# CBASS_HC2_0_QOS register map
Vendor: Texas Instruments
Peripheral module from a debugger description file (folder J7_AHP).
Registers are 32-bit, read-write, reset 0x7000 unless marked. A register's access mark holds for its fields unless they carry their own. Offsets are as the file gives them; lines under a group give offsets from that group; [hi:lo] are bit positions; {n}, {i} and the like mark numbered series; 'fields as' and 'values as' point back to an identical list; <NAME> marks a mode.

## CBASS_HC2_0_QOS
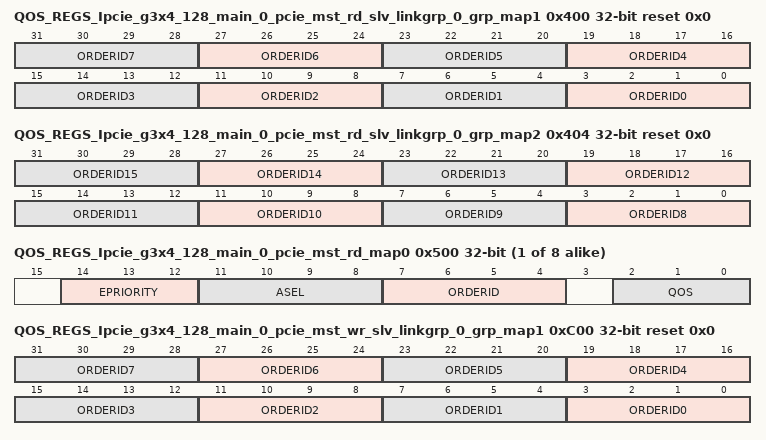
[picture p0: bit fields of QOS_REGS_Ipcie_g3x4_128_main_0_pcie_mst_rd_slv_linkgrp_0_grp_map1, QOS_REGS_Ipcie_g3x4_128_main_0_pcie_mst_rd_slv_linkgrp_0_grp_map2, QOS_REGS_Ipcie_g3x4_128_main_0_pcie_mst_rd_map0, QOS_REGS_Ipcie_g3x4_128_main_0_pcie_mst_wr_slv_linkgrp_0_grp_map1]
0x400 QOS_REGS_Ipcie_g3x4_128_main_0_pcie_mst_rd_slv_linkgrp_0_grp_map1 reset 0x0
  [4n+3:4n] ORDERID{n} (n=0..7) — orderid signal for {n}.
0x404 QOS_REGS_Ipcie_g3x4_128_main_0_pcie_mst_rd_slv_linkgrp_0_grp_map2 reset 0x0
  [4n-29:4n-32] ORDERID{n} (n=8..15) — orderid signal for {n-8}.
{0x500+4i} QOS_REGS_Ipcie_g3x4_128_main_0_pcie_mst_rd_map{i} (i=0..7)
  [14:12] EPRIORITY — epriority signal for channel N.
  [11:8] ASEL — asel signal for channel N. 0 = SOC address. 1-15 = peripheral address.
  [7:4] ORDERID — orderid signal for channel N.
  [2:0] QOS — qos signal for channel N.
0xC00 QOS_REGS_Ipcie_g3x4_128_main_0_pcie_mst_wr_slv_linkgrp_0_grp_map1 reset 0x0
  [4n+3:4n] ORDERID{n} (n=0..7) — orderid signal for {n}.
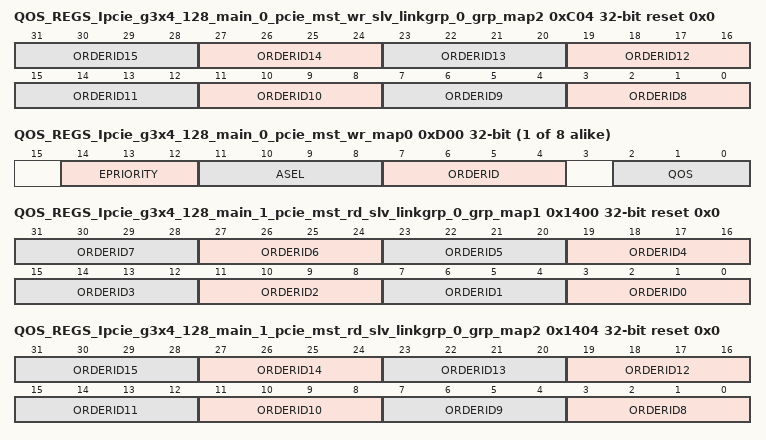
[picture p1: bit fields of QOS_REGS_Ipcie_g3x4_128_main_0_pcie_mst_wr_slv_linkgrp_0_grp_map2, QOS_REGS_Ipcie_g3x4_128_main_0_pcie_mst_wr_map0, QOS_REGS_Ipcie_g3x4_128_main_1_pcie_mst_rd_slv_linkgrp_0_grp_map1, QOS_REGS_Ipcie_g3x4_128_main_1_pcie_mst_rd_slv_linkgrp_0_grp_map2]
0xC04 QOS_REGS_Ipcie_g3x4_128_main_0_pcie_mst_wr_slv_linkgrp_0_grp_map2 reset 0x0
  [4n-29:4n-32] ORDERID{n} (n=8..15) — orderid signal for {n-8}.
{0xD00+4i} QOS_REGS_Ipcie_g3x4_128_main_0_pcie_mst_wr_map{i} (i=0..7)
  fields as QOS_REGS_Ipcie_g3x4_128_main_0_pcie_mst_rd_map0
0x1400 QOS_REGS_Ipcie_g3x4_128_main_1_pcie_mst_rd_slv_linkgrp_0_grp_map1 reset 0x0
  [4n+3:4n] ORDERID{n} (n=0..7) — orderid signal for {n}.
0x1404 QOS_REGS_Ipcie_g3x4_128_main_1_pcie_mst_rd_slv_linkgrp_0_grp_map2 reset 0x0
  [4n-29:4n-32] ORDERID{n} (n=8..15) — orderid signal for {n-8}.
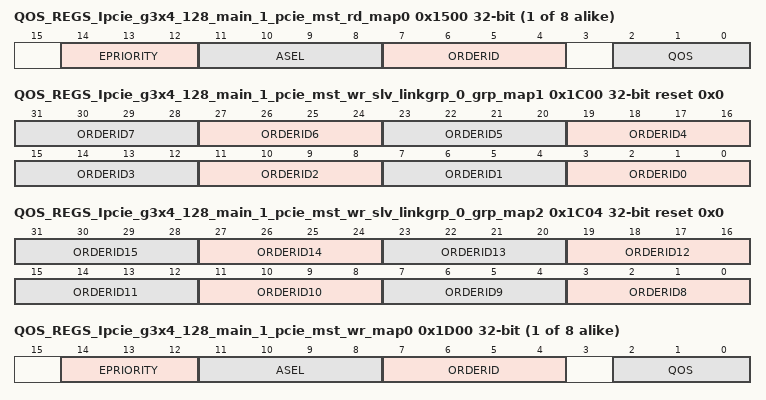
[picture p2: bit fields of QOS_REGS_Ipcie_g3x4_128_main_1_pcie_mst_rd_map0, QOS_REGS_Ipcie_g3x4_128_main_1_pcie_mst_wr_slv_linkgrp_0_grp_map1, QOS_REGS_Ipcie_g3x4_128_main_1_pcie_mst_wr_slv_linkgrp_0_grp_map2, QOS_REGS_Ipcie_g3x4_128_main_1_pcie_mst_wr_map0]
{0x1500+4i} QOS_REGS_Ipcie_g3x4_128_main_1_pcie_mst_rd_map{i} (i=0..7)
  fields as QOS_REGS_Ipcie_g3x4_128_main_0_pcie_mst_rd_map0
0x1C00 QOS_REGS_Ipcie_g3x4_128_main_1_pcie_mst_wr_slv_linkgrp_0_grp_map1 reset 0x0
  [4n+3:4n] ORDERID{n} (n=0..7) — orderid signal for {n}.
0x1C04 QOS_REGS_Ipcie_g3x4_128_main_1_pcie_mst_wr_slv_linkgrp_0_grp_map2 reset 0x0
  [4n-29:4n-32] ORDERID{n} (n=8..15) — orderid signal for {n-8}.
{0x1D00+4i} QOS_REGS_Ipcie_g3x4_128_main_1_pcie_mst_wr_map{i} (i=0..7)
  fields as QOS_REGS_Ipcie_g3x4_128_main_0_pcie_mst_rd_map0
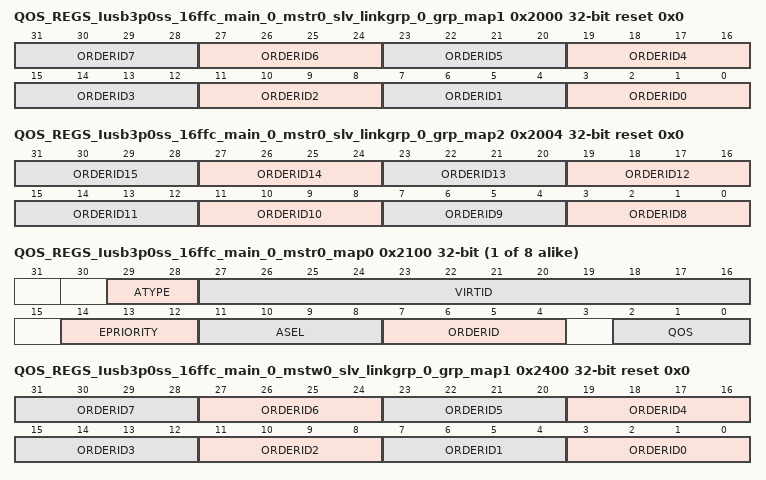
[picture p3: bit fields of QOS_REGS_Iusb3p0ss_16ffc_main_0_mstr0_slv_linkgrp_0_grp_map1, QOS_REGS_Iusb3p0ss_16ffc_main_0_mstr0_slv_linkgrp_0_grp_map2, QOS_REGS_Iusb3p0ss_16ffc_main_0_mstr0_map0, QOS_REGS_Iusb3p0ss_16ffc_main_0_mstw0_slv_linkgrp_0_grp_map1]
0x2000 QOS_REGS_Iusb3p0ss_16ffc_main_0_mstr0_slv_linkgrp_0_grp_map1 reset 0x0
  [4n+3:4n] ORDERID{n} (n=0..7) — orderid signal for {n}.
0x2004 QOS_REGS_Iusb3p0ss_16ffc_main_0_mstr0_slv_linkgrp_0_grp_map2 reset 0x0
  [4n-29:4n-32] ORDERID{n} (n=8..15) — orderid signal for {n-8}.
{0x2100+4i} QOS_REGS_Iusb3p0ss_16ffc_main_0_mstr0_map{i} (i=0..7)
  [29:28] ATYPE — epriority signal for channel N. 0 = physical. 1 = intermediate. 2 = virtual. 3 = physical with coherence.
  [27:16] VIRTID — virtid signal for channel N.
  [14:12] EPRIORITY — epriority signal for channel N.
  [11:8] ASEL — asel signal for channel N. 0 = SOC address. 1-15 = peripheral address.
  [7:4] ORDERID — orderid signal for channel N.
  [2:0] QOS — qos signal for channel N.
0x2400 QOS_REGS_Iusb3p0ss_16ffc_main_0_mstw0_slv_linkgrp_0_grp_map1 reset 0x0
  [4n+3:4n] ORDERID{n} (n=0..7) — orderid signal for {n}.
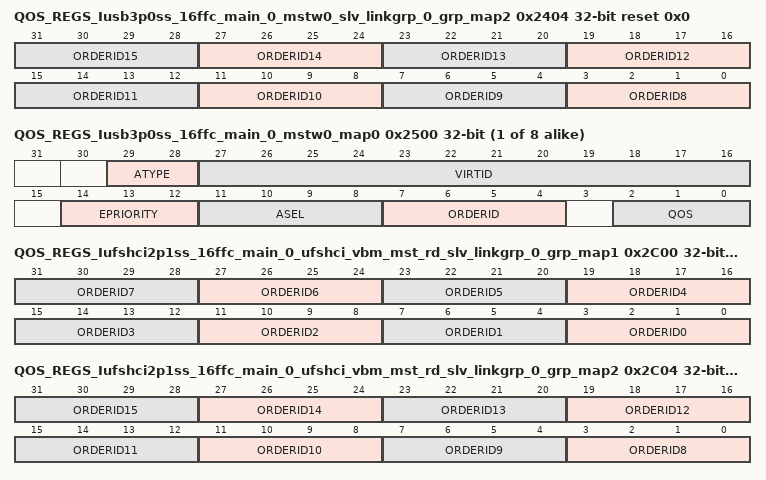
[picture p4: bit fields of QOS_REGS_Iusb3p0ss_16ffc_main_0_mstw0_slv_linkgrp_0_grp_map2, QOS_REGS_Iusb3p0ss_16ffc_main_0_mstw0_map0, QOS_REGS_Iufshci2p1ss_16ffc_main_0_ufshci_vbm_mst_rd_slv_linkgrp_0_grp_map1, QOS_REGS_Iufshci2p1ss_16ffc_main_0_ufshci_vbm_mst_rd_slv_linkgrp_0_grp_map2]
0x2404 QOS_REGS_Iusb3p0ss_16ffc_main_0_mstw0_slv_linkgrp_0_grp_map2 reset 0x0
  [4n-29:4n-32] ORDERID{n} (n=8..15) — orderid signal for {n-8}.
{0x2500+4i} QOS_REGS_Iusb3p0ss_16ffc_main_0_mstw0_map{i} (i=0..7)
  fields as QOS_REGS_Iusb3p0ss_16ffc_main_0_mstr0_map0
0x2C00 QOS_REGS_Iufshci2p1ss_16ffc_main_0_ufshci_vbm_mst_rd_slv_linkgrp_0_grp_map1 reset 0x0
  [4n+3:4n] ORDERID{n} (n=0..7) — orderid signal for {n}.
0x2C04 QOS_REGS_Iufshci2p1ss_16ffc_main_0_ufshci_vbm_mst_rd_slv_linkgrp_0_grp_map2 reset 0x0
  [4n-29:4n-32] ORDERID{n} (n=8..15) — orderid signal for {n-8}.
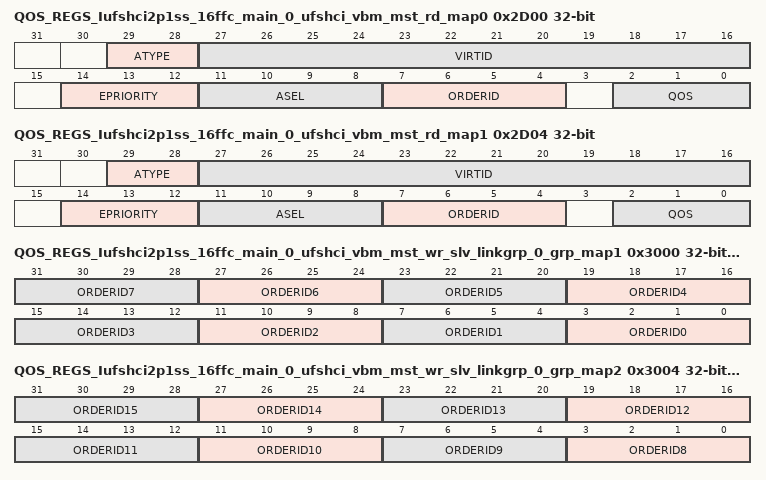
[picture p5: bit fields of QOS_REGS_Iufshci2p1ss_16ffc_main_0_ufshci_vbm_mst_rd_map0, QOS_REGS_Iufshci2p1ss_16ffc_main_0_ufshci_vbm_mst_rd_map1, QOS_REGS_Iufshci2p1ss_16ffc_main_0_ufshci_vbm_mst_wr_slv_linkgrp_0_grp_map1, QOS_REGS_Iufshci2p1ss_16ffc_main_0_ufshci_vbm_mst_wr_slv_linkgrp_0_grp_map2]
0x2D00 QOS_REGS_Iufshci2p1ss_16ffc_main_0_ufshci_vbm_mst_rd_map0
  fields as QOS_REGS_Iusb3p0ss_16ffc_main_0_mstr0_map0
0x2D04 QOS_REGS_Iufshci2p1ss_16ffc_main_0_ufshci_vbm_mst_rd_map1
  fields as QOS_REGS_Iusb3p0ss_16ffc_main_0_mstr0_map0
0x3000 QOS_REGS_Iufshci2p1ss_16ffc_main_0_ufshci_vbm_mst_wr_slv_linkgrp_0_grp_map1 reset 0x0
  [4n+3:4n] ORDERID{n} (n=0..7) — orderid signal for {n}.
0x3004 QOS_REGS_Iufshci2p1ss_16ffc_main_0_ufshci_vbm_mst_wr_slv_linkgrp_0_grp_map2 reset 0x0
  [4n-29:4n-32] ORDERID{n} (n=8..15) — orderid signal for {n-8}.
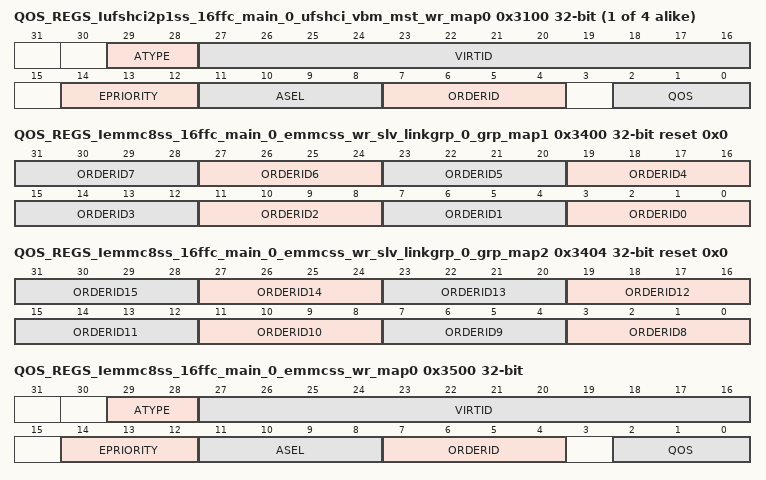
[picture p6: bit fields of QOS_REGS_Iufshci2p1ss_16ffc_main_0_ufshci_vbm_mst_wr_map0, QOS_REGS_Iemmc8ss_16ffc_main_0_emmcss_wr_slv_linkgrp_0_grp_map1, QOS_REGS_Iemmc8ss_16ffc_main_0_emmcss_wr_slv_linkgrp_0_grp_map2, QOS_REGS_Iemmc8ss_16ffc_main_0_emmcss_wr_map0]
{0x3100+4i} QOS_REGS_Iufshci2p1ss_16ffc_main_0_ufshci_vbm_mst_wr_map{i} (i=0..3)
  fields as QOS_REGS_Iusb3p0ss_16ffc_main_0_mstr0_map0
0x3400 QOS_REGS_Iemmc8ss_16ffc_main_0_emmcss_wr_slv_linkgrp_0_grp_map1 reset 0x0
  [4n+3:4n] ORDERID{n} (n=0..7) — orderid signal for {n}.
0x3404 QOS_REGS_Iemmc8ss_16ffc_main_0_emmcss_wr_slv_linkgrp_0_grp_map2 reset 0x0
  [4n-29:4n-32] ORDERID{n} (n=8..15) — orderid signal for {n-8}.
0x3500 QOS_REGS_Iemmc8ss_16ffc_main_0_emmcss_wr_map0
  fields as QOS_REGS_Iusb3p0ss_16ffc_main_0_mstr0_map0
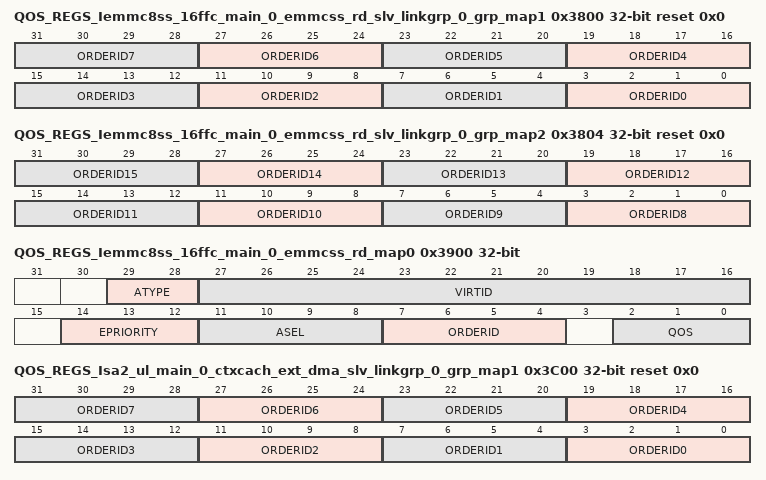
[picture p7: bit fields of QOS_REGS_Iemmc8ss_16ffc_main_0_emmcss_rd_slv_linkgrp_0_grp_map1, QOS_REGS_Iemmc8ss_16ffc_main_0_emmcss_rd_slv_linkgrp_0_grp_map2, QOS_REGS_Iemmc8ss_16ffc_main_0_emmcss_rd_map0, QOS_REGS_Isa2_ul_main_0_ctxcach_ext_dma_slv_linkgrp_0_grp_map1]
0x3800 QOS_REGS_Iemmc8ss_16ffc_main_0_emmcss_rd_slv_linkgrp_0_grp_map1 reset 0x0
  [4n+3:4n] ORDERID{n} (n=0..7) — orderid signal for {n}.
0x3804 QOS_REGS_Iemmc8ss_16ffc_main_0_emmcss_rd_slv_linkgrp_0_grp_map2 reset 0x0
  [4n-29:4n-32] ORDERID{n} (n=8..15) — orderid signal for {n-8}.
0x3900 QOS_REGS_Iemmc8ss_16ffc_main_0_emmcss_rd_map0
  fields as QOS_REGS_Iusb3p0ss_16ffc_main_0_mstr0_map0
0x3C00 QOS_REGS_Isa2_ul_main_0_ctxcach_ext_dma_slv_linkgrp_0_grp_map1 reset 0x0
  [4n+3:4n] ORDERID{n} (n=0..7) — orderid signal for {n}.
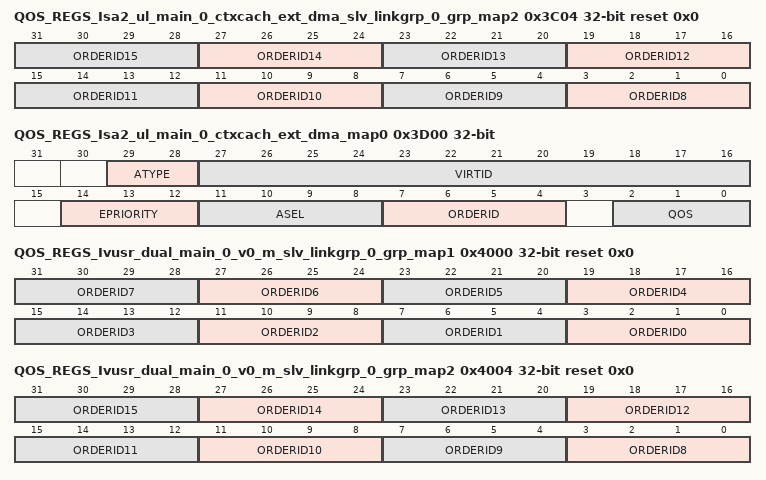
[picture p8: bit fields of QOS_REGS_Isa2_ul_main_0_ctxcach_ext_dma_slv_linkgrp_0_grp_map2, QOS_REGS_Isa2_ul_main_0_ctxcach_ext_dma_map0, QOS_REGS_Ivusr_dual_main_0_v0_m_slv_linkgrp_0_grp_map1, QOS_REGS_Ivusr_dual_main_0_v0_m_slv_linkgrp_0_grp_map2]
0x3C04 QOS_REGS_Isa2_ul_main_0_ctxcach_ext_dma_slv_linkgrp_0_grp_map2 reset 0x0
  [4n-29:4n-32] ORDERID{n} (n=8..15) — orderid signal for {n-8}.
0x3D00 QOS_REGS_Isa2_ul_main_0_ctxcach_ext_dma_map0
  fields as QOS_REGS_Iusb3p0ss_16ffc_main_0_mstr0_map0
0x4000 QOS_REGS_Ivusr_dual_main_0_v0_m_slv_linkgrp_0_grp_map1 reset 0x0
  [4n+3:4n] ORDERID{n} (n=0..7) — orderid signal for {n}.
0x4004 QOS_REGS_Ivusr_dual_main_0_v0_m_slv_linkgrp_0_grp_map2 reset 0x0
  [4n-29:4n-32] ORDERID{n} (n=8..15) — orderid signal for {n-8}.
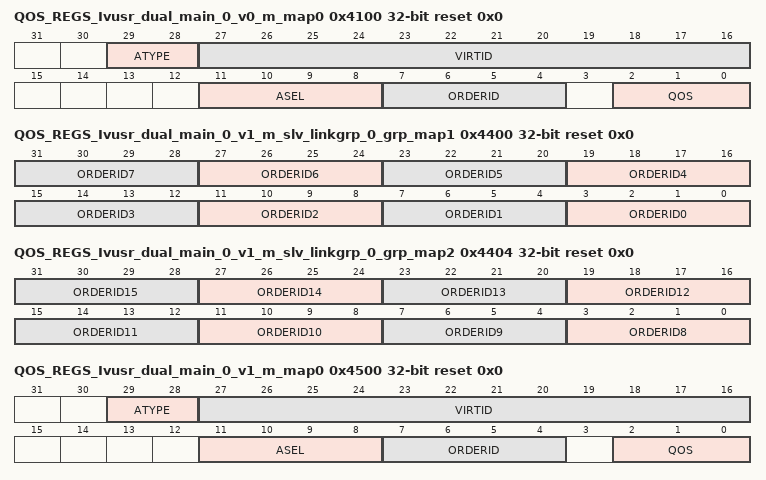
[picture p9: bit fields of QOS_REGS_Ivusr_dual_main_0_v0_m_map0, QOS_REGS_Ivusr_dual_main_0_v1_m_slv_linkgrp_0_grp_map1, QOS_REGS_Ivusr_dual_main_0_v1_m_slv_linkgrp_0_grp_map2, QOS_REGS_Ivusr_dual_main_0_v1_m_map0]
0x4100 QOS_REGS_Ivusr_dual_main_0_v0_m_map0 reset 0x0
  [29:28] ATYPE — epriority signal for channel N. 0 = physical. 1 = intermediate. 2 = virtual. 3 = physical with coherence.
  [27:16] VIRTID — virtid signal for channel N.
  [11:8] ASEL — asel signal for channel N. 0 = SOC address. 1-15 = peripheral address.
  [7:4] ORDERID — orderid signal for channel N.
  [2:0] QOS — qos signal for channel N.
0x4400 QOS_REGS_Ivusr_dual_main_0_v1_m_slv_linkgrp_0_grp_map1 reset 0x0
  [4n+3:4n] ORDERID{n} (n=0..7) — orderid signal for {n}.
0x4404 QOS_REGS_Ivusr_dual_main_0_v1_m_slv_linkgrp_0_grp_map2 reset 0x0
  [4n-29:4n-32] ORDERID{n} (n=8..15) — orderid signal for {n-8}.
0x4500 QOS_REGS_Ivusr_dual_main_0_v1_m_map0 reset 0x0
  fields as QOS_REGS_Ivusr_dual_main_0_v0_m_map0
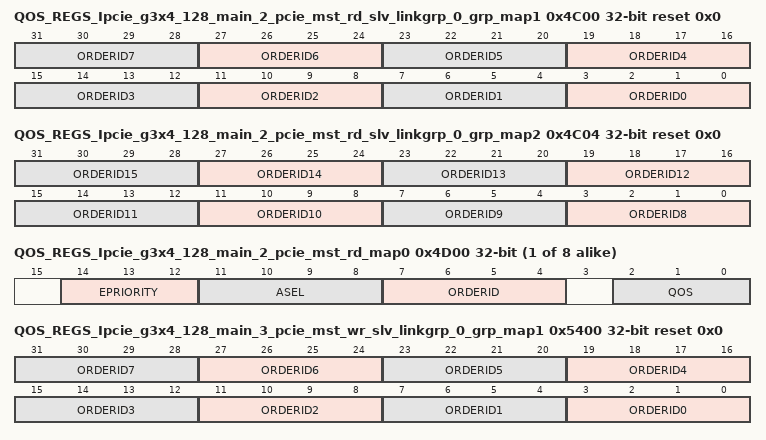
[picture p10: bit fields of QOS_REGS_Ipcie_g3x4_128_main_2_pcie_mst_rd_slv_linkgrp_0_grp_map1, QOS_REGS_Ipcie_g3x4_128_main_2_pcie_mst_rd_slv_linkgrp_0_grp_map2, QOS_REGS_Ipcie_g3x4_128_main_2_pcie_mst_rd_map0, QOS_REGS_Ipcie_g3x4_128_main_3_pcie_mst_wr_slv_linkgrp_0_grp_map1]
0x4C00 QOS_REGS_Ipcie_g3x4_128_main_2_pcie_mst_rd_slv_linkgrp_0_grp_map1 reset 0x0
  [4n+3:4n] ORDERID{n} (n=0..7) — orderid signal for {n}.
0x4C04 QOS_REGS_Ipcie_g3x4_128_main_2_pcie_mst_rd_slv_linkgrp_0_grp_map2 reset 0x0
  [4n-29:4n-32] ORDERID{n} (n=8..15) — orderid signal for {n-8}.
{0x4D00+4i} QOS_REGS_Ipcie_g3x4_128_main_2_pcie_mst_rd_map{i} (i=0..7)
  fields as QOS_REGS_Ipcie_g3x4_128_main_0_pcie_mst_rd_map0
0x5400 QOS_REGS_Ipcie_g3x4_128_main_3_pcie_mst_wr_slv_linkgrp_0_grp_map1 reset 0x0
  [4n+3:4n] ORDERID{n} (n=0..7) — orderid signal for {n}.
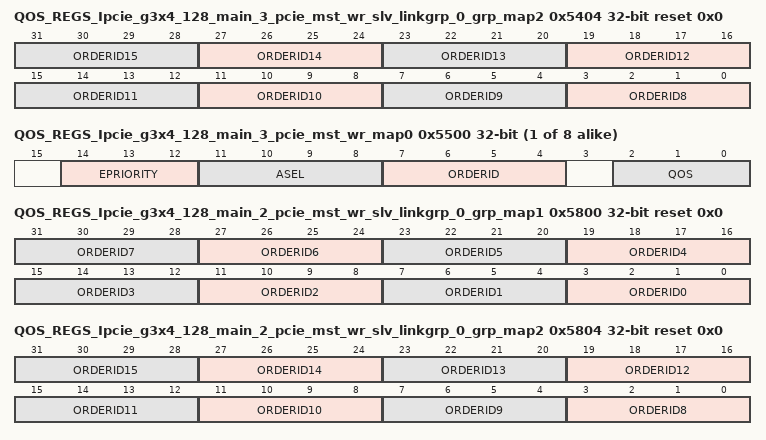
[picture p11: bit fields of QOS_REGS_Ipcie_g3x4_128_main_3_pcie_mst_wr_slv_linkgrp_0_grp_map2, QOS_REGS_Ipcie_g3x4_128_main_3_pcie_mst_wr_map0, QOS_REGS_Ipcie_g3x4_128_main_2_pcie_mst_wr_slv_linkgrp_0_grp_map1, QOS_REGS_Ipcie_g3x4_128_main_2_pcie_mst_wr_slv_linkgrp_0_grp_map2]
0x5404 QOS_REGS_Ipcie_g3x4_128_main_3_pcie_mst_wr_slv_linkgrp_0_grp_map2 reset 0x0
  [4n-29:4n-32] ORDERID{n} (n=8..15) — orderid signal for {n-8}.
{0x5500+4i} QOS_REGS_Ipcie_g3x4_128_main_3_pcie_mst_wr_map{i} (i=0..7)
  fields as QOS_REGS_Ipcie_g3x4_128_main_0_pcie_mst_rd_map0
0x5800 QOS_REGS_Ipcie_g3x4_128_main_2_pcie_mst_wr_slv_linkgrp_0_grp_map1 reset 0x0
  [4n+3:4n] ORDERID{n} (n=0..7) — orderid signal for {n}.
0x5804 QOS_REGS_Ipcie_g3x4_128_main_2_pcie_mst_wr_slv_linkgrp_0_grp_map2 reset 0x0
  [4n-29:4n-32] ORDERID{n} (n=8..15) — orderid signal for {n-8}.
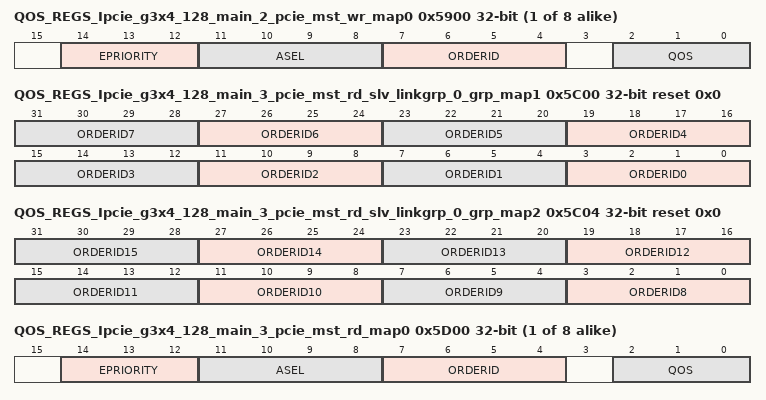
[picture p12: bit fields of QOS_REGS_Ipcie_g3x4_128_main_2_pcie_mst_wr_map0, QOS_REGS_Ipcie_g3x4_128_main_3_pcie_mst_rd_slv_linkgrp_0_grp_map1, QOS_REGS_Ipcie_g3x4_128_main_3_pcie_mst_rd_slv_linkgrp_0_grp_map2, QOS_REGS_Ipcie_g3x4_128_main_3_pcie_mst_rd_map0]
{0x5900+4i} QOS_REGS_Ipcie_g3x4_128_main_2_pcie_mst_wr_map{i} (i=0..7)
  fields as QOS_REGS_Ipcie_g3x4_128_main_0_pcie_mst_rd_map0
0x5C00 QOS_REGS_Ipcie_g3x4_128_main_3_pcie_mst_rd_slv_linkgrp_0_grp_map1 reset 0x0
  [4n+3:4n] ORDERID{n} (n=0..7) — orderid signal for {n}.
0x5C04 QOS_REGS_Ipcie_g3x4_128_main_3_pcie_mst_rd_slv_linkgrp_0_grp_map2 reset 0x0
  [4n-29:4n-32] ORDERID{n} (n=8..15) — orderid signal for {n-8}.
{0x5D00+4i} QOS_REGS_Ipcie_g3x4_128_main_3_pcie_mst_rd_map{i} (i=0..7)
  fields as QOS_REGS_Ipcie_g3x4_128_main_0_pcie_mst_rd_map0
